# Musca register map
Vendor: ARM Ltd.; Series: ARMv8-M Mainline; File version: 1.0
CPU: CM33 r0p1, little endian, MPU, no FPU, 3 interrupt priority bits, 8 SAU regions
Registers are 32-bit, read-write, reset 0x0 unless marked. A register's access mark holds for its fields unless they carry their own. Offsets are from the block's base; [hi:lo] are bit positions; 'fields as' and 'values as' point back to an identical list.

## TIMER0
Base 0x40000000
Same registers: TIMER1 0x40001000, S32KTIMER 0x4002F000, TIMER0_Secure 0x50000000, TIMER1_Secure 0x50001000, S32KTIMER_Secure 0x5002F000
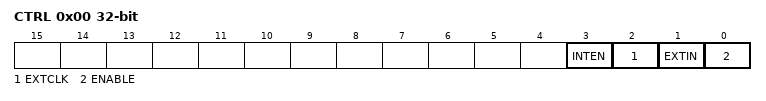
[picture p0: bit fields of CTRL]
0x00 CTRL — Control Register
  [3] INTEN — Interrupt Enable
    0=Disable (Interrupt is disabled); 1=Enable (Interrupt is enabled)
  [2] EXTCLK — External Clock Enable
    0=Disable (External Clock is disabled); 1=Enable (External Clock is enabled)
  [1] EXTIN — External Input as Enable
    0=Disable (External Input as Enable is disabled); 1=Enable (External Input as Enable is enabled)
  [0] ENABLE
    0=Disable (Timer is disabled); 1=Enable (Timer is enabled)
0x04 VALUE — Current Timer Counter Value
0x08 RELOAD — Counter Reload Value
0x0C INTSTATUS ro — Timer Interrupt status register
0x0C INTCLEAR wo write-1-clears (alternate view of INTSTATUS) — Timer Interrupt clear register

## DUALTIMER
Base 0x40002000
Same registers: DUALTIMER_Secure 0x50002000
0x00 TIMER1LOAD
0x04 TIMER1VALUE ro reset 0xFFFFFFFF
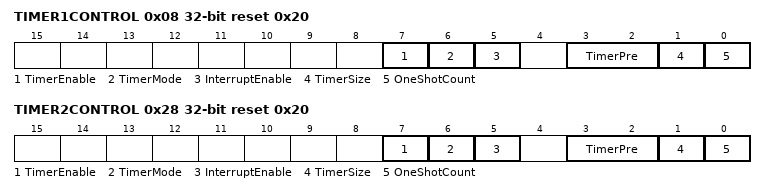
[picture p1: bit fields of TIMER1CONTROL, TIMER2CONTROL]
0x08 TIMER1CONTROL reset 0x20
  [7] TimerEnable — Timer Enable Enable bit.
    0=Disable (Timer is disabled.); 1=Enable (Timer is enabled.)
  [6] TimerMode — Timer Mode bit.
    0=Free-Running timer mode; 1=Periodic timer mode
  [5] InterruptEnable — Interrupt Enable bit.
    0=Disable (Interrupt is disabled.); 1=Enable (Interrupt is enabled.)
  [3:2] TimerPre — Timer prescale bits.
    0=divided by 1 (clock is divided by 1); 1=divided by 16 (clock is divided by 16); 2=divided by 256 (clock is divided by 256)
  [1] TimerSize — Selects 16-bit or 32- bit counter operation.
    0=16-bit counter mode; 1=32-bit counter mode
  [0] OneShotCount — Selects one-shot or wrapping counter mode.
    0=Wrapping counter mode; 1=One-shot counter mode
0x0C TIMER1INTCLR wo — Timer 1 Interrupt Clear Register
  [0] INT write-1-clears — Interrupt
0x10 TIMER1RIS ro — Timer 1 Raw Interrupt Status Register
  [0] RIS — Raw Timer Interrupt
0x14 TIMER1MIS ro — Timer 1 Mask Interrupt Status Register
  [0] MIS — Masked Timer Interrupt
0x18 TIMER1BGLOAD — Timer 1 Background Load Register
0x20 TIMER2LOAD
0x24 TIMER2VALUE ro reset 0xFFFFFFFF
0x28 TIMER2CONTROL reset 0x20
  fields as TIMER1CONTROL
0x2C TIMER2INTCLR wo — Timer 2 Interrupt Clear Register
  [0] INT write-1-clears — Interrupt
0x30 TIMER2RIS ro — Timer 2 Raw Interrupt Status Register
  [0] RIS — Raw Timer Interrupt
0x34 TIMER2MIS ro — Timer 2 Mask Interrupt Status Register
  [0] MIS — Masked Timer Interrupt
0x38 TIMER2BGLOAD — Timer 2 Background Load Register

## GPIO0 — General-purpose I/O 0
Base 0x40110000
Same registers: GPIO0_Secure 0x50110000
0x00 DATA
0x04 DATAOUT — Data Output Register
0x10 OUTENSET — Ouptut enable set Register
0x14 OUTENCLR — Ouptut enable clear Register
0x18 ALTFUNCSET — Alternate function set Register
0x1C ALTFUNCCLR — Alternate function clear Register
0x20 INTENSET — Interrupt enable set Register
0x24 INTENCLR — Interrupt enable clear Register
0x28 INTTYPESET — Interrupt type set Register
0x2C INTTYPECLR — Interrupt type clear Register
0x30 INTPOLSET — Polarity-level, edge interrupt configuration set Register
0x34 INTPOLCLR — Polarity-level, edge interrupt configuration clear Register
0x38 INTSTATUS ro — Interrupt Status Register
0x38 INTCLEAR wo write-1-clears (alternate view of INTSTATUS) — Interrupt CLEAR Register

## WATCHDOG — Non-secure Watchdog Timer
Base 0x40081000
Same registers: S32KWATCHDOG 0x4002E000, S32KWATCHDOG_Secure 0x5002E000, WATCHDOG_Secure 0x50081000
0x00 WDOGLOAD reset 0xFFFFFFFF — Watchdog Load Register
0x04 WDOGVALUE ro reset 0xFFFFFFFF — Watchdog Value Register
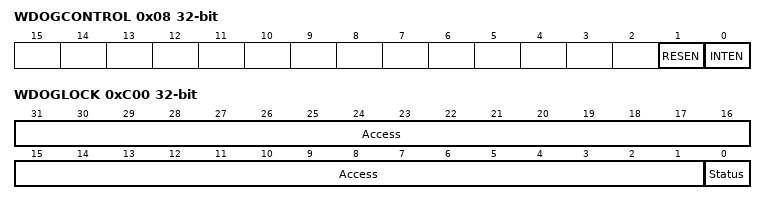
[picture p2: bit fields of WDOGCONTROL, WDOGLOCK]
0x08 WDOGCONTROL — Watchdog Control Register
  [1] RESEN — Enable watchdog reset output
    0=Disable Watchdog reset; 1=Enable Watchdog reset
  [0] INTEN — Enable the interrupt event
    0=Disable Watchdog interrupt; 1=Enable Watchdog interrupt
0x0C WDOGINTCLR wo — Watchdog Interrupt Clear Register
  [0] INT write-1-clears — Interrupt
0x10 WDOGRIS ro — Watchdog Raw Interrupt Status Register
  [0] RIS — Raw watchdog Interrupt
0x14 WDOGMIS ro — Watchdog Mask Interrupt Status Register
  [0] MIS — Masked Watchdog Interrupt
0xC00 WDOGLOCK — Watchdog Lock Register
  [31:1] Access — Enable register writes
  [0] Status — Register write enable status
    0=Enabled (Write access to all other registers is enabled. This is the default.); 1=Disabled (Write access to all other registers is disabled.)

## Notices in the file
Copyright (C) 2012-2017 ARM Limited. All rights reserved.
Purpose: System Viewer Description (SVD) Example (Schema Version 1.1)
This is a description of a none-existent and incomplete device
for demonstration purposes only.
Redistribution and use in source and binary forms, with or without
modification, are permitted provided that the following conditions are met:
- Redistributions of source code must retain the above copyright
notice, this list of conditions and the following disclaimer.
- Redistributions in binary form must reproduce the above copyright
notice, this list of conditions and the following disclaimer in the
documentation and/or other materials provided with the distribution.
- Neither the name of ARM nor the names of its contributors may be used
to endorse or promote products derived from this software without
specific prior written permission.
THIS SOFTWARE IS PROVIDED BY THE COPYRIGHT HOLDERS AND CONTRIBUTORS "AS IS"
AND ANY EXPRESS OR IMPLIED WARRANTIES, INCLUDING, BUT NOT LIMITED TO, THE
IMPLIED WARRANTIES OF MERCHANTABILITY AND FITNESS FOR A PARTICULAR PURPOSE
ARE DISCLAIMED. IN NO EVENT SHALL COPYRIGHT HOLDERS AND CONTRIBUTORS BE
LIABLE FOR ANY DIRECT, INDIRECT, INCIDENTAL, SPECIAL, EXEMPLARY, OR
CONSEQUENTIAL DAMAGES (INCLUDING, BUT NOT LIMITED TO, PROCUREMENT OF
SUBSTITUTE GOODS OR SERVICES; LOSS OF USE, DATA, OR PROFITS; OR BUSINESS
INTERRUPTION) HOWEVER CAUSED AND ON ANY THEORY OF LIABILITY, WHETHER IN
CONTRACT, STRICT LIABILITY, OR TORT (INCLUDING NEGLIGENCE OR OTHERWISE)
ARISING IN ANY WAY OUT OF THE USE OF THIS SOFTWARE, EVEN IF ADVISED OF THE
POSSIBILITY OF SUCH DAMAGE.
